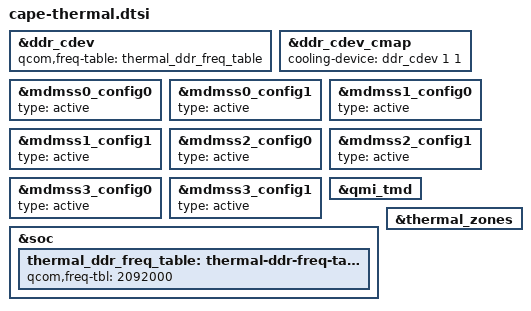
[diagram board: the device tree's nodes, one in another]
// SPDX-License-Identifier: BSD-3-Clause
/*
 * Copyright (c) Qualcomm Technologies, Inc. and/or its subsidiaries.
 */

&ddr_cdev {
	qcom,freq-table = <&thermal_ddr_freq_table>;
};

&ddr_cdev_cmap {
	cooling-device = <&ddr_cdev 1 1>;
};

&mdmss0_config0 {
	type = "active";
};

&mdmss0_config1 {
	type = "active";
};

&mdmss1_config0 {
	type = "active";
};

&mdmss1_config1 {
	type = "active";
};

&mdmss2_config0 {
	type = "active";
};

&mdmss2_config1 {
	type = "active";
};

&mdmss3_config0 {
	type = "active";
};

&mdmss3_config1 {
	type = "active";
};

&qmi_tmd {
	/delete-node/ cdsp_usr;
	/delete-node/ modem_usr;
};

&soc {
	thermal_ddr_freq_table: thermal-ddr-freq-table {
		qcom,freq-tbl = <2092000>;
	};
};

&thermal_zones {
	/delete-node/ cx-pe;
};
